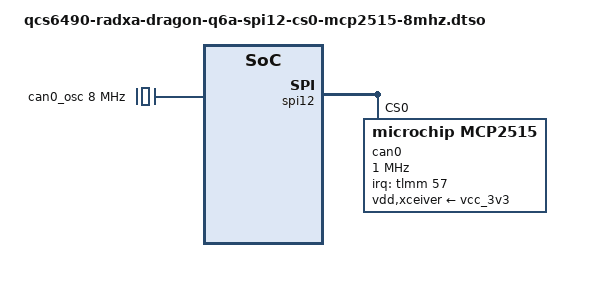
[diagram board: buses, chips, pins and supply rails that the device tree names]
// SPDX-License-Identifier: BSD-3-Clause
/*
 * Copyright (c) 2025 Radxa Computer (Shenzhen) Co., Ltd.
 */

/dts-v1/;
/plugin/;

#include <dt-bindings/gpio/gpio.h>
#include <dt-bindings/interrupt-controller/irq.h>

/ {
	metadata {
		title = "Enable MCP2515 with 8MHz external clock on SPI12 over CS0";
		compatible = "radxa,dragon-q6a";
		category = "misc";
		exclusive = "spi12", "uart12", "i2c12", "gpio48", "gpio49", "gpio50", "gpio51", "GPIO_57";
		description = "Enable MCP2515 with 8MHz external clock on SPI12 over CS0.

Provide support for Microchip MCP2515 SPI CAN controller.
Assumes 8MHz external clock.
Uses Pin 22 (GPIO_57) for INT.";
	};
};

&i2c12 {
	status = "disabled";
};

&uart12 {
	status = "disabled";
};

&spi12 {
	qcom,enable-gsi-dma;
	status = "okay";
	max-freq = <1000000>;
	#address-cells = <1>;
	#size-cells = <0>;

	can0: mcp2515@0 {
		compatible = "microchip,mcp2515";
		status = "okay";
		reg = <0>;
		spi-max-frequency = <1000000>;

		interrupt-parent = <&tlmm>;
		interrupts = <57 IRQ_TYPE_EDGE_FALLING>;

		clocks = <&can0_osc>;
		vdd-supply = <&vcc_3v3>;
		xceiver-supply = <&vcc_3v3>;
	};
};

&{/} {
	can0_osc: can0-osc {
		compatible = "fixed-clock";
		#clock-cells = <0>;
		clock-frequency  = <8000000>;
	};
};
